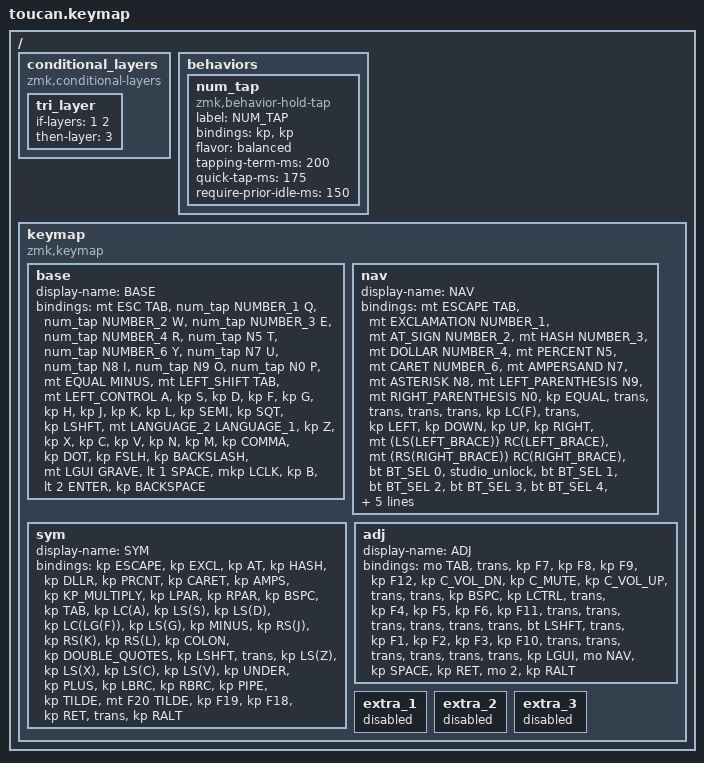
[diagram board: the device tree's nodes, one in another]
#include <behaviors.dtsi>
#include <dt-bindings/zmk/bt.h>
#include <dt-bindings/zmk/keys.h>
#include <dt-bindings/zmk/pointing.h>

#define BASE 0
#define NAV  1
#define SYM  2
#define ADJ  3

/ {
    conditional_layers {
        compatible = "zmk,conditional-layers";

        tri_layer {
            if-layers = <1 2>;
            then-layer = <3>;
        };
    };

    behaviors {
        // アルゴリズムを「balanced」に統一し、位置指定の干渉をすべて排除
        num_tap: num_tap {
            compatible = "zmk,behavior-hold-tap";
            label = "NUM_TAP";
            bindings = <&kp>, <&kp>;
            #binding-cells = <2>;
            
            flavor = "balanced";
            tapping-term-ms = <200>;         // 200ms間しっかり押しっぱなしにしないと数字にならない
            quick-tap-ms = <175>;            // 同じキーの連打を快適にする
            require-prior-idle-ms = <150>;   // タイピング中に指が滑って重なっても文字入力を強制優先する
        };
    };

    keymap {  
        compatible = "zmk,keymap";

        base {
            display-name = "BASE";
            bindings = <
&mt ESC TAB  &num_tap NUMBER_1 Q  &num_tap NUMBER_2 W  &num_tap NUMBER_3 E  &num_tap NUMBER_4 R  &num_tap N5 T  &num_tap NUMBER_6 Y  &num_tap N7 U  &num_tap N8 I  &num_tap N9 O  &num_tap N0 P  &mt EQUAL MINUS  &mt LEFT_SHIFT TAB  &mt LEFT_CONTROL A  &kp S  &kp D  &kp F  &kp G  &kp H  &kp J  &kp K  &kp L  &kp SEMI  &kp SQT  &kp LSHFT  &mt LANGUAGE_2 LANGUAGE_1  &kp Z  &kp X  &kp C  &kp V  &kp N  &kp M  &kp COMMA  &kp DOT  &kp FSLH  &kp BACKSLASH  &mt LGUI GRAVE  &lt 1 SPACE  &mkp LCLK  &kp B  &lt 2 ENTER  &kp BACKSPACE
            >; 
        };

        nav {
            display-name = "NAV";
            bindings = <
&mt ESCAPE TAB  &mt EXCLAMATION NUMBER_1  &mt AT_SIGN NUMBER_2  &mt HASH NUMBER_3  &mt DOLLAR NUMBER_4  &mt PERCENT N5  &mt CARET NUMBER_6  &mt AMPERSAND N7  &mt ASTERISK N8  &mt LEFT_PARENTHESIS N9  &mt RIGHT_PARENTHESIS N0  &kp EQUAL  &trans  &trans  &trans  &trans  &kp LC(F)  &trans  &kp LEFT  &kp DOWN  &kp UP  &kp RIGHT  &mt (LS(LEFT_BRACE)) RC(LEFT_BRACE)  &mt (RS(RIGHT_BRACE)) RC(RIGHT_BRACE)  &bt BT_SEL 0  &studio_unlock  &bt BT_SEL 1  &bt BT_SEL 2  &bt BT_SEL 3  &bt BT_SEL 4  &kp LS(NUMBER_6)  &trans  &kt LESS_THAN  &kp GREATER_THAN  &kp LEFT_BRACKET  &kp RIGHT_BRACKET  &kp LGUI  &trans  &kp SPACE  &kp RET  &kp RS(NUMBER_6)  &kp RG(RA(BACKSPACE))
            >;
        };

        sym {
            display-name = "SYM";
            bindings = <
&kp ESCAPE  &kp EXCL  &kp AT  &kp HASH  &kp DLLR  &kp PRCNT  &kp CARET  &kp AMPS  &kp KP_MULTIPLY  &kp LPAR  &kp RPAR  &kp BSPC  &kp TAB  &kp LC(A)  &kp LS(S)  &kp LS(D)  &kp LC(LG(F))  &kp LS(G)  &kp MINUS  &kp RS(J)  &kp RS(K)  &kp RS(L)  &kp COLON  &kp DOUBLE_QUOTES  &kp LSHFT  &trans  &kp LS(Z)  &kp LS(X)  &kp LS(C)  &kp LS(V)  &kp UNDER  &kp PLUS  &kp LBRC  &kp RBRC  &kp PIPE  &kp TILDE  &mt F20 TILDE  &kp F19  &kp F18  &kp RET  &trans  &kp RALT
            >;
        };

        adj {
            display-name = "ADJ";
            bindings = <
&mo TAB  &trans  &kp F7  &kp F8  &kp F9  &kp F12  &kp C_VOL_DN  &kp C_MUTE  &kp C_VOL_UP  &trans  &trans  &kp BSPC  &kp LCTRL  &trans  &kp F4  &kp F5  &kp F6  &kp F11  &trans  &trans  &trans  &trans  &trans  &trans  &bt LSHFT  &trans  &kp F1  &kp F2  &kp F3  &kp F10  &trans  &trans  &trans  &trans  &trans  &trans  &kp LGUI  &mo NAV  &kp SPACE  &kp RET  &mo 2  &kp RALT
            >;
        };

        extra_1 { status = "reserved"; };

        extra_2 { status = "reserved"; };

        extra_3 { status = "reserved"; };
    };
};
